# APM32F41x register map
File version: 1.0
CPU: CM4 r1p0, little endian, no MPU, no FPU, 3 interrupt priority bits
Registers are 32-bit, read-write, reset 0x0 unless marked. A register's access mark holds for its fields unless they carry their own. Offsets are from the block's base; [hi:lo] are bit positions.

## USART6 — Universal synchronous asynchronous receiver transmitter
Base 0x40011400
Same registers: USART2 0x40004400, USART3 0x40004800, USART1 0x40011000
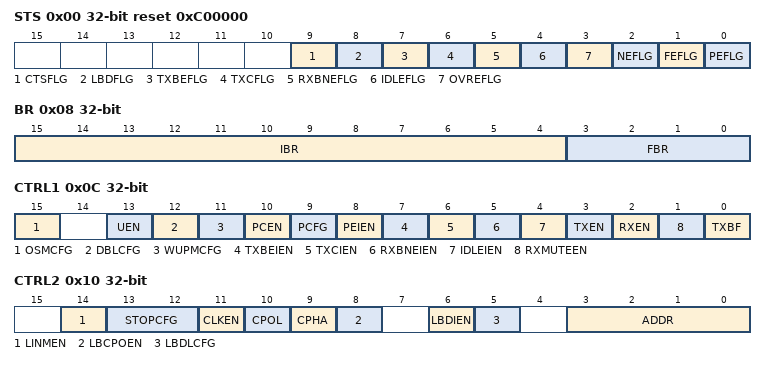
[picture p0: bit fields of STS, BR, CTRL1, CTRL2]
0x00 STS access per field reset 0xC00000 — Status register
  [9] CTSFLG rw — CTS flag
  [8] LBDFLG rw — LIN break detection flag
  [7] TXBEFLG ro — Transmit data register empty
  [6] TXCFLG rw — Transmission complete
  [5] RXBNEFLG rw — Read data register not empty
  [4] IDLEFLG ro — IDLE line detected
  [3] OVREFLG ro — Overrun error
  [2] NEFLG ro — Noise detected flag
  [1] FEFLG ro — Framing error
  [0] PEFLG ro — Parity error
0x04 DATA
  [8:0] DATA — Data value
0x08 BR — Baud rate register
  [15:4] IBR — mantissa of USARTDIV
  [3:0] FBR — fraction of USARTDIV
0x0C CTRL1 — Control register 1
  [15] OSMCFG — Oversampling mode
  [13] UEN — USART enable
  [12] DBLCFG — Word length
  [11] WUPMCFG — Wakeup method
  [10] PCEN — Parity control enable
  [9] PCFG — Parity selection
  [8] PEIEN — Parity Error Interrupt Enable
  [7] TXBEIEN — Transmit Buffer Empty Interrupt Enable
  [6] TXCIEN — Transmission complete interrupt enable
  [5] RXBNEIEN — RXNE interrupt enable
  [4] IDLEIEN — IDLE interrupt enable
  [3] TXEN — Transmitter enable
  [2] RXEN — Receiver enable
  [1] RXMUTEEN — Receiver wakeup
  [0] TXBF — Send break
0x10 CTRL2 — Control register 2
  [14] LINMEN — LIN mode enable
  [13:12] STOPCFG — STOP bits
  [11] CLKEN — Clock enable
  [10] CPOL — Clock polarity
  [9] CPHA — Clock phase
  [8] LBCPOEN — Last bit clock pulse
  [6] LBDIEN — LIN break detection interrupt enable
  [5] LBDLCFG — lin break detection length
  [3:0] ADDR — Address of the USART node
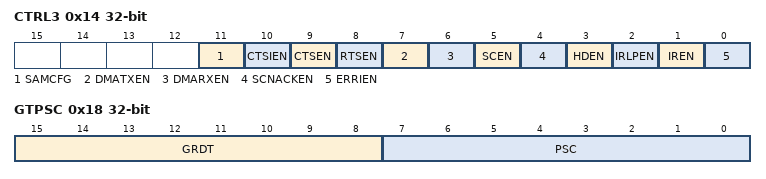
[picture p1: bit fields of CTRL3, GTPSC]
0x14 CTRL3 — Control register 3
  [11] SAMCFG — One sample bit method enable
  [10] CTSIEN — CTS interrupt enable
  [9] CTSEN — CTS enable
  [8] RTSEN — RTS enable
  [7] DMATXEN — DMA enable transmitter
  [6] DMARXEN — DMA enable receiver
  [5] SCEN — Smartcard mode enable
  [4] SCNACKEN — Smartcard NACK enable
  [3] HDEN — Half-duplex selection
  [2] IRLPEN — IrDA low-power
  [1] IREN — IrDA mode enable
  [0] ERRIEN — Error interrupt enable
0x18 GTPSC — Guard time and prescaler register
  [15:8] GRDT — Guard time value
  [7:0] PSC — Prescaler value

## DAC — Digital-to-analog converter
Base 0x40007400
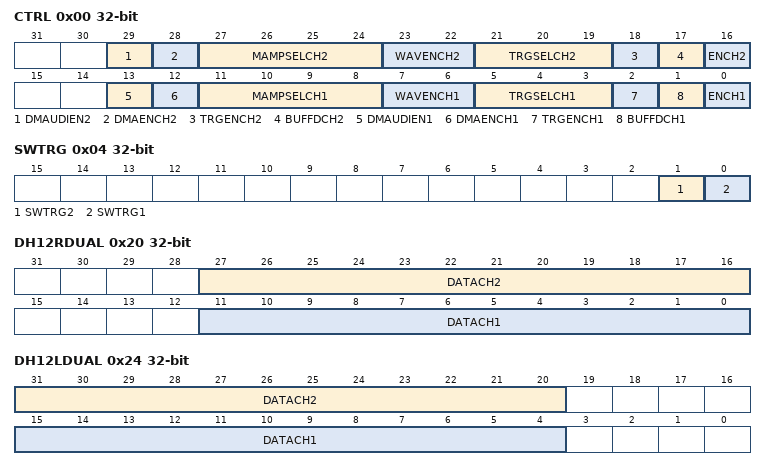
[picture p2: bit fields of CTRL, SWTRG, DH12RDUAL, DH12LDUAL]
0x00 CTRL — control register
  [29] DMAUDIEN2 — DAC channel2 DMA underrun interrupt enable
  [28] DMAENCH2 — DAC channel2 DMA enable
  [27:24] MAMPSELCH2 — DAC channel2 mask/amplitude selector
  [23:22] WAVENCH2 — DAC channel2 noise/triangle wave generation enable
  [21:19] TRGSELCH2 — DAC channel2 trigger selection
  [18] TRGENCH2 — DAC channel2 trigger enable
  [17] BUFFDCH2 — DAC channel2 output buffer disable
  [16] ENCH2 — DAC channel2 enable
  [13] DMAUDIEN1 — DAC channel1 DMA Underrun Interrupt enable
  [12] DMAENCH1 — DAC channel1 DMA enable
  [11:8] MAMPSELCH1 — DAC channel1 mask/amplitude selector
  [7:6] WAVENCH1 — DAC channel1 noise/triangle wave generation enable
  [5:3] TRGSELCH1 — DAC channel1 trigger selection
  [2] TRGENCH1 — DAC channel1 trigger enable
  [1] BUFFDCH1 — DAC channel1 output buffer disable
  [0] ENCH1 — DAC channel1 enable
0x04 SWTRG wo — software trigger register
  [1] SWTRG2 — DAC channel2 software trigger
  [0] SWTRG1 — DAC channel1 software trigger
0x08 DH12R1 — channel1 12-bit right-aligned data holding register
  [11:0] DATA — DAC channel1 12-bit right-aligned data
0x0C DH12L1 — channel1 12-bit left aligned data holding register
  [15:4] DATA — DAC channel1 12-bit left-aligned data
0x10 DH8R1 — channel1 8-bit right aligned data holding register
  [7:0] DATA — DAC channel1 8-bit right-aligned data
0x14 DH12R2 — channel2 12-bit right aligned data holding register
  [11:0] DATA — DAC channel2 12-bit right-aligned data
0x18 DH12L2 — channel2 12-bit left aligned data holding register
  [15:4] DATA — DAC channel2 12-bit left-aligned data
0x1C DH8R2 — channel2 8-bit right-aligned data holding register
  [7:0] DATA — DAC channel2 8-bit right-aligned data
0x20 DH12RDUAL — Dual DAC 12-bit right-aligned data holding register
  [27:16] DATACH2 — DAC channel2 12-bit right-aligned data
  [11:0] DATACH1 — DAC channel1 12-bit right-aligned data
0x24 DH12LDUAL — DUAL DAC 12-bit left aligned data holding register
  [31:20] DATACH2 — DAC channel2 12-bit left-aligned data
  [15:4] DATACH1 — DAC channel1 12-bit left-aligned data
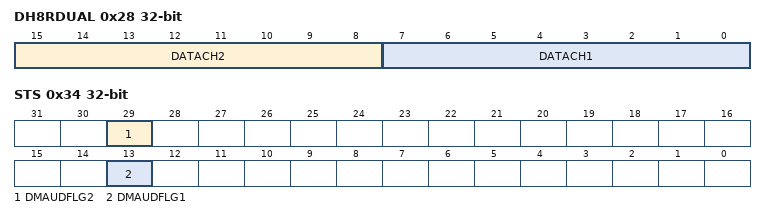
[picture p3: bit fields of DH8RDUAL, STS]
0x28 DH8RDUAL — DUAL DAC 8-bit right aligned data holding register
  [15:8] DATACH2 — DAC channel2 8-bit right-aligned data
  [7:0] DATACH1 — DAC channel1 8-bit right-aligned data
0x2C DATAOCH1 ro — channel1 data output register
  [11:0] DATA — DAC channel1 data output
0x30 DATAOCH2 ro — channel2 data output register
  [11:0] DATA — DAC channel2 data output
0x34 STS — status register
  [29] DMAUDFLG2 — DAC channel2 DMA underrun flag
  [13] DMAUDFLG1 — DAC channel1 DMA underrun flag
